# MKW36Z4 register map
Vendor: NXP Semiconductors; Series: Kinetis_W; File version: 1.6
CPU: CM0PLUS r0p0, little endian, no MPU, no FPU, VTOR, 2 interrupt priority bits
Registers are 16-bit, read-write, no defined reset value unless marked. A register's access mark holds for its fields unless they carry their own. Offsets are from the block's base; [hi:lo] are bit positions; 'fields as' and 'values as' point back to an identical list.

## DCDC — DC to DC Converter
Base 0x4005A000; register names take the prefix DCDC_
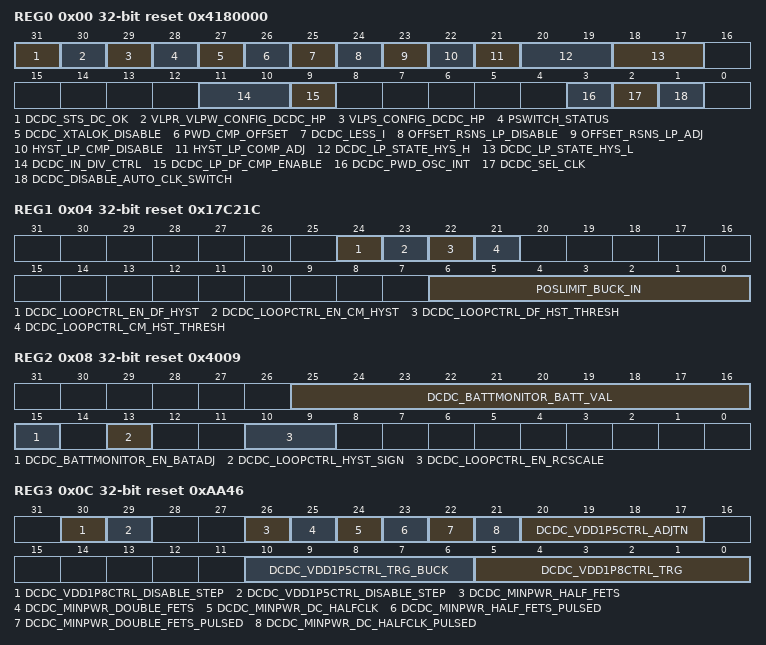
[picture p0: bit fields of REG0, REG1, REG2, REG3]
0x00 REG0 32-bit reset 0x4180000 — DCDC REGISTER 0
  [31] DCDC_STS_DC_OK ro — Status bit to indicate that the DCDC output voltage is stable
    0=Unstable DCDC output voltage; 1=Stable DCDC output voltage
  [30] VLPR_VLPW_CONFIG_DCDC_HP — Selects behavior of DCDC in device VLPR and VLPW low power modes
    0=DCDC works in pulsed mode when SoC is in VLPR / VLPW modes; 1=DCDC works in continuous mode when SoC is in VLPR / VLPW modes
  [29] VLPS_CONFIG_DCDC_HP — Selects behavior of DCDC in device VLPS low power mode
    0=DCDC works in pulsed mode when SOC is in VLPS modes; 1=DCDC works in continuous mode when SOC is in VLPS modes
  [28] PSWITCH_STATUS ro — Status bit to indicate PSWITCH status
    0=PSWITCH is low; 1=PSWITCH is high
  [27] DCDC_XTALOK_DISABLE — Disable xtalok detection circuit
  [26] PWD_CMP_OFFSET — Output range comparator monitors the output voltage of DCDC
    0=Output range comparator powered up; 1=Output range comparator powered down
  [25] DCDC_LESS_I — Reduces DCDC current by reducing the analog reference current inside the DCDC Converter
    0=Use normal current for analog references; 1=Use reduced current for analog references
  [24] OFFSET_RSNS_LP_DISABLE — Disable hysteresis in low power voltage sense
    0=Hysteresis feature is enabled; 1=Hysteresis feature is disabled
  [23] OFFSET_RSNS_LP_ADJ — Adjust hysteretic value in low power voltage sense
    0=Adjustment feature is disabled; 1=Adjustment feature is enabled
  [22] HYST_LP_CMP_DISABLE — Disable hysteresis in low power comparator
    values as OFFSET_RSNS_LP_DISABLE
  [21] HYST_LP_COMP_ADJ — Adjust hysteretic value in low power comparator
    values as OFFSET_RSNS_LP_ADJ
  [20:19] DCDC_LP_STATE_HYS_H — Configure the hysteretic upper threshold value in low power mode
    0=Target voltage value + 0 mV; 1=Target voltage value + 25 mV; 2=Target voltage value + 50 mV; 3=Target voltage value + 75 mV
  [18:17] DCDC_LP_STATE_HYS_L — Configure the hysteretic lower threshold value in low power mode
    0=Target voltage value - 0 mV; 1=Target voltage value - 25 mV; 2=Target voltage value - 50 mV; 3=Target voltage value - 75 mV
  [11:10] DCDC_IN_DIV_CTRL — Controls DCDC_IN voltage divider
    0=OFF; 1=DCDC_IN; 2=DCDC_IN / 2; 3=DCDC_IN / 4
  [9] DCDC_LP_DF_CMP_ENABLE — Enable low power differential comparators, to sense lower supply in pulsed mode
    1=DCDC compare the lower supply(relative to target value) with DCDC_LP_STATE_HYS_L. When it is lower than DCDC_LP_STATE_HYS_L, re-charge output. This is the recommended configuration to guarantee optimal operation; 0=DCDC compare the common mode sense of supply(relative to target value) with DCDC_LP_STATE_HYS_L. When it is lower than DCDC_LP_STATE_HYS_L, re-charge output.
  [3] DCDC_PWD_OSC_INT — Power down internal oscillator. Only set this bit when 32M crystal oscillator is available.
    0=Internal oscillator is powered up; 1=Internal oscillator is powered down
  [2] DCDC_SEL_CLK — Select external clock for DCDC when DCDC_DISABLE_AUTO_CLK_SWITCH is set.
    0=Internal oscillator is used as DCDC clock; 1=External oscillator is used as DCDC clock
  [1] DCDC_DISABLE_AUTO_CLK_SWITCH — Disable automatic clock switch from internal oscillator to external clock.
    0=Automatic clock switch feature is enabled; 1=Automatic clock switch feature is disabled
0x04 REG1 32-bit reset 0x17C21C — DCDC REGISTER 1
  [24] DCDC_LOOPCTRL_EN_DF_HYST — Enable hysteresis in switching converter differential mode analog comparators
  [23] DCDC_LOOPCTRL_EN_CM_HYST — Enable hysteresis in switching converter common mode analog comparators
  [22] DCDC_LOOPCTRL_DF_HST_THRESH — Enable hysteresis in switching converter differential mode analog comparators
  [21] DCDC_LOOPCTRL_CM_HST_THRESH — Enable hysteresis in switching converter common mode analog comparators
  [6:0] POSLIMIT_BUCK_IN — Upper limit duty cycle limit in DCDC converter
0x08 REG2 32-bit reset 0x4009 — DCDC REGISTER 2
  [25:16] DCDC_BATTMONITOR_BATT_VAL — Software should write the VDCDC_IN in this register measured with an 8 mV LSB resolution through the ADC
  [15] DCDC_BATTMONITOR_EN_BATADJ — This bit enables the DCDC to improve efficiency and minimize ripple using the information from the BATT_VAL field
    0=Disable the usage of the DCDC_BATTMONITOR_BATT_VAL value to calculate DCDC loop control; 1=Enable the usage of DCDC_BATTMONITOR_BATT_VAL value to calculate DCDC loop control
  [13] DCDC_LOOPCTRL_HYST_SIGN — This bit ensures proper switching of DCDC in Pulsed mode and is set in Pulsed mode.
    0=Hysteresis sign not inverted; 1=Hysteresis sign inverted (proper switching gauranteed)
  [10:9] DCDC_LOOPCTRL_EN_RCSCALE — The DCDC_LOOPCTRL_EN_RCSCALE reduces the response time of the DCDC to transient loads.
    0=Default response time; 1=2 times faster than default; 2=4 times faster than default
0x0C REG3 32-bit reset 0xAA46 — DCDC REGISTER 3
  [30] DCDC_VDD1P8CTRL_DISABLE_STEP — Disable stepping for VDD_1P8. Must set this bit before enter low power modes.
    0=VDD_1P8 stepping enabled; 1=VDD_1P8 stepping disabled
  [29] DCDC_VDD1P5CTRL_DISABLE_STEP — Disable stepping for VDD_1P5. Must set this bit before enter low power modes.
    0=VDD_1P5 stepping enabled; 1=VDD_1P5 stepping disabled
  [26] DCDC_MINPWR_HALF_FETS — Use half switch FET for the continuous mode
    0=Normal operation; 1=Use Half FET
  [25] DCDC_MINPWR_DOUBLE_FETS — Use double switch FET for the continuous mode
    0=Normal operation; 1=Use Double FET
  [24] DCDC_MINPWR_DC_HALFCLK — Set DCDC clock to half frequency for the continuous mode.
    0=Normal operation for DCDC clock; 1=DCDC clock operates at half frequency
  [23] DCDC_MINPWR_HALF_FETS_PULSED — Use half switch FET for the Pulsed mode
    0=Pulsed mode uses normal output configuration; 1=Pulsed mode uses half FET output configuration
  [22] DCDC_MINPWR_DOUBLE_FETS_PULSED — Use double switch FET for the Pulsed mode
    0=Pulsed mode uses normal output configuration; 1=Pulsed mode uses double FET output configuration
  [21] DCDC_MINPWR_DC_HALFCLK_PULSED — Set DCDC clock to half frequency for the Pulsed mode.
    0=Pulsed mode uses normal operation for DCDC clock; 1=Pulsed mode uses half frequency DCDC clock operation
  [20:17] DCDC_VDD1P5CTRL_ADJTN — Adjust value of duty cycle when switching between VDD_1P5 and VDD_1P8
  [10:6] DCDC_VDD1P5CTRL_TRG_BUCK — Target value of VDD_1P5 in buck mode, 25 mV each step from 0x00 to 0x0F Code VDD_1P8 Output Target (V) 0x00 1
  [5:0] DCDC_VDD1P8CTRL_TRG — Target value of VDD_1P8 : 25 mV each step in two ranges, from 0x00 to 0x11 and 0x20 to 0x3F and 50 mV each step in range from 0x12 to 0x1F
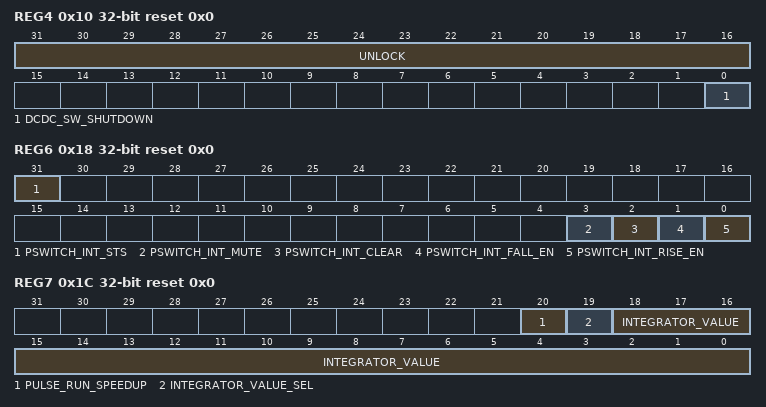
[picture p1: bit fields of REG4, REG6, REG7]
0x10 REG4 32-bit reset 0x0 — DCDC REGISTER 4
  [31:16] UNLOCK — 0x3E77 KEY-Key needed to unlock DCDC_REG4 register
  [0] DCDC_SW_SHUTDOWN — Shut down DCDC in buck mode. DCDC can be turned on by pulling PSWITCH to high momentarily (DCDC Turn on time (TDCDC_ON; refer to the data sheet for specific time). This bit should not be used in buck mode when PSWITCH is tied to DCDC_IN.
0x18 REG6 32-bit reset 0x0 — DCDC REGISTER 6
  [31] PSWITCH_INT_STS ro — PSWITCH edge detection interrupt status
    0=PSWITCH interrupt has not occurred; 1=PSWITCH interrupt has occurred
  [3] PSWITCH_INT_MUTE — Mask interrupt to SoC, edge detection result can be read from PSIWTCH_INT_STS.
  [2] PSWITCH_INT_CLEAR — This bit clears the PSWITCH interrupt.
    0=No effect; 1=Clear PSWITCH interrupt
  [1] PSWITCH_INT_FALL_EN — Enable falling edge detect for interrupt.
    0=PSWITCH falling edge interrupt disabled; 1=PSWITCH falling edge interrupt enabled
  [0] PSWITCH_INT_RISE_EN — Enable rising edge detect for interrupt.
    0=PSWITCH rising edge interrupt disabled; 1=PSWITCH rising edge interrupt enabled
0x1C REG7 32-bit reset 0x0 — DCDC REGISTER 7
  [20] PULSE_RUN_SPEEDUP — Enable pulse run speedup
    0=Pulse run speedup feature disabled; 1=Pulse run speedup feature enabled
  [19] INTEGRATOR_VALUE_SEL — Select the integrator value from above register or saved value in hardware.
    0=Select the saved value in hardware; 1=Select the integrator value in this register
  [18:0] INTEGRATOR_VALUE — Integrator value which can be loaded in pulsed mode
